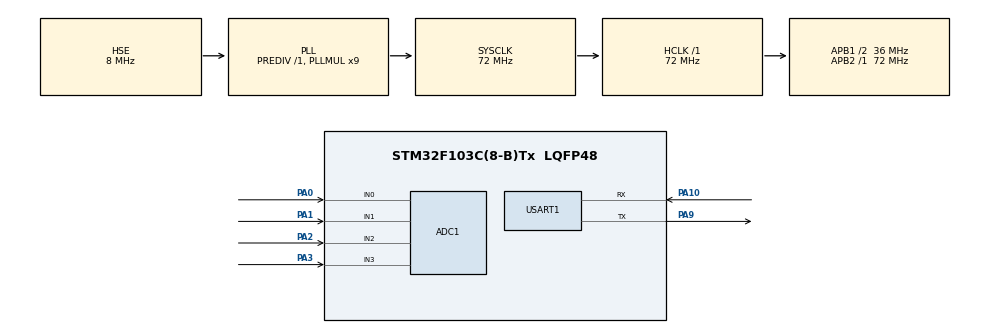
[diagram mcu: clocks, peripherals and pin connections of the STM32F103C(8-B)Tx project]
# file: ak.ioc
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ADC1.Channel-10\#ChannelRegularConversion=ADC_CHANNEL_0
ADC1.Channel-11\#ChannelRegularConversion=ADC_CHANNEL_0
ADC1.Channel-12\#ChannelRegularConversion=ADC_CHANNEL_0
ADC1.Channel-13\#ChannelRegularConversion=ADC_CHANNEL_0
ADC1.DiscontinuousConvMode=ENABLE
ADC1.NbrOfConversion=4
ADC1.NbrOfConversionFlag=1
ADC1.Rank-10\#ChannelRegularConversion=1
ADC1.Rank-11\#ChannelRegularConversion=2
ADC1.Rank-12\#ChannelRegularConversion=3
ADC1.Rank-13\#ChannelRegularConversion=4
ADC1.SamplingTime-10\#ChannelRegularConversion=ADC_SAMPLETIME_1CYCLE_5
ADC1.SamplingTime-11\#ChannelRegularConversion=ADC_SAMPLETIME_1CYCLE_5
ADC1.SamplingTime-12\#ChannelRegularConversion=ADC_SAMPLETIME_1CYCLE_5
ADC1.SamplingTime-13\#ChannelRegularConversion=ADC_SAMPLETIME_1CYCLE_5
ADC1.master=1
Dma.ADC1.0.Direction=DMA_PERIPH_TO_MEMORY
Dma.ADC1.0.Instance=DMA1_Channel1
Dma.ADC1.0.MemDataAlignment=DMA_MDATAALIGN_HALFWORD
Dma.ADC1.0.MemInc=DMA_MINC_ENABLE
Dma.ADC1.0.Mode=DMA_NORMAL
Dma.ADC1.0.PeriphDataAlignment=DMA_PDATAALIGN_HALFWORD
Dma.ADC1.0.PeriphInc=DMA_PINC_DISABLE
Dma.ADC1.0.Priority=DMA_PRIORITY_LOW
Dma.Request0=ADC1
Mcu.Family=STM32F1
Mcu.Name=STM32F103C(8-B)Tx
Mcu.Package=LQFP48
NVIC.DMA1_Channel1_IRQn=true\:0\:0\:false\:false\:true\:false\:true\:true
NVIC.PriorityGroup=NVIC_PRIORITYGROUP_4
NVIC.USART1_IRQn=true\:0\:0\:false\:false\:true\:true\:true\:true
PA0-WKUP.Signal=ADCx_IN0
PA1.Signal=ADCx_IN1
PA10.Mode=Asynchronous
PA10.Signal=USART1_RX
PA2.Signal=ADCx_IN2
PA3.Signal=ADCx_IN3
PA9.Mode=Asynchronous
PA9.Signal=USART1_TX
PD0-OSC_IN.Mode=HSE-External-Oscillator
PD0-OSC_IN.Signal=RCC_OSC_IN
PD1-OSC_OUT.Mode=HSE-External-Oscillator
PD1-OSC_OUT.Signal=RCC_OSC_OUT
ProjectManager.HeapSize=0x200
ProjectManager.StackSize=0x400
ProjectManager.TargetToolchain=MDK-ARM V5.32
RCC.ADCPresc=RCC_ADCPCLK2_DIV6
RCC.AHBFreq_Value=72000000
RCC.APB1CLKDivider=RCC_HCLK_DIV2
RCC.APB1Freq_Value=36000000
RCC.APB1TimFreq_Value=72000000
RCC.APB2Freq_Value=72000000
RCC.APB2TimFreq_Value=72000000
RCC.HCLKFreq_Value=72000000
RCC.PLLMUL=RCC_PLL_MUL9
RCC.PLLSourceVirtual=RCC_PLLSOURCE_HSE
RCC.SYSCLKFreq_VALUE=72000000
RCC.SYSCLKSource=RCC_SYSCLKSOURCE_PLLCLK
RCC.USBFreq_Value=72000000
SH.ADCx_IN0.0=ADC1_IN0,IN0
SH.ADCx_IN1.0=ADC1_IN1,IN1
SH.ADCx_IN2.0=ADC1_IN2,IN2
SH.ADCx_IN3.0=ADC1_IN3,IN3
USART1.VirtualMode=VM_ASYNC
VP_SYS_VS_ND.Mode=No_Debug
board=custom

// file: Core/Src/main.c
/* USER CODE BEGIN Header */
/**
  ******************************************************************************
  * @file           : main.c
  * @brief          : Main program body
  ******************************************************************************
  * @attention
  *
  * Copyright (c) 2022 STMicroelectronics.
  * All rights reserved.
  *
  * This software is licensed under terms that can be found in the LICENSE file
  * in the root directory of this software component.
  * If no LICENSE file comes with this software, it is provided AS-IS.
  *
  ******************************************************************************
  */
/* USER CODE END Header */
#include "main.h"
#include "string.h"
#include "stdio.h"

ADC_HandleTypeDef hadc1;
DMA_HandleTypeDef hdma_adc1;

UART_HandleTypeDef huart1;

void SystemClock_Config(void);
static void MX_GPIO_Init(void);
static void MX_DMA_Init(void);
static void MX_USART1_UART_Init(void);
static void MX_ADC1_Init(void);
/* USER CODE BEGIN PFP */
uint8_t ADC[10] = {0};
/* USER CODE END PFP */

/* USER CODE BEGIN 0 */
volatile uint16_t adcReadVal[4] = {0};
const int adcChannelCount = sizeof(adcReadVal)/sizeof(adcReadVal[0]);
volatile char adcConversionComplete = 0;
char txBuffer[36] = {0};
/* USER CODE END 0 */

int main(void)
{

  /* MCU Configuration--------------------------------------------------------*/

  /* Reset of all peripherals, Initializes the Flash interface and the Systick. */
  HAL_Init();

  /* Configure the system clock */
  SystemClock_Config();

  /* Initialize all configured peripherals */
  MX_GPIO_Init();
  MX_DMA_Init();
  MX_USART1_UART_Init();
  MX_ADC1_Init();
  /* Infinite loop */
  while (1)
  {
		HAL_ADC_Start_DMA(&hadc1,(uint32_t*)adcReadVal,adcChannelCount);
//		while(adcConversionComplete == 0)
//		{
//
//		}
		snprintf(txBuffer,sizeof(txBuffer),"CH0:%d,CH1:%d,CH2:%d,CH3:%d\n\r",adcReadVal[0],adcReadVal[1],adcReadVal[2],adcReadVal[3]);
		HAL_UART_Transmit(&huart1,(uint8_t*)txBuffer,strlen(txBuffer),HAL_MAX_DELAY);
		HAL_Delay(1000);
  }
}

void HAL_ADC_ConvCpltCallback(ADC_HandleTypeDef *hadc)
{
	adcConversionComplete = 1;
}
void SystemClock_Config(void)
{
  RCC_OscInitTypeDef RCC_OscInitStruct = {0};
  RCC_ClkInitTypeDef RCC_ClkInitStruct = {0};
  RCC_PeriphCLKInitTypeDef PeriphClkInit = {0};

  /** Initializes the RCC Oscillators according to the specified parameters
  * in the RCC_OscInitTypeDef structure.
  */
  RCC_OscInitStruct.OscillatorType = RCC_OSCILLATORTYPE_HSE;
  RCC_OscInitStruct.HSEState = RCC_HSE_ON;
  RCC_OscInitStruct.HSEPredivValue = RCC_HSE_PREDIV_DIV1;
  RCC_OscInitStruct.HSIState = RCC_HSI_ON;
  RCC_OscInitStruct.PLL.PLLState = RCC_PLL_ON;
  RCC_OscInitStruct.PLL.PLLSource = RCC_PLLSOURCE_HSE;
  RCC_OscInitStruct.PLL.PLLMUL = RCC_PLL_MUL9;
  if (HAL_RCC_OscConfig(&RCC_OscInitStruct) != HAL_OK)
  {
    Error_Handler();
  }

  /** Initializes the CPU, AHB and APB buses clocks
  */
  RCC_ClkInitStruct.ClockType = RCC_CLOCKTYPE_HCLK|RCC_CLOCKTYPE_SYSCLK
                              |RCC_CLOCKTYPE_PCLK1|RCC_CLOCKTYPE_PCLK2;
  RCC_ClkInitStruct.SYSCLKSource = RCC_SYSCLKSOURCE_PLLCLK;
  RCC_ClkInitStruct.AHBCLKDivider = RCC_SYSCLK_DIV1;
  RCC_ClkInitStruct.APB1CLKDivider = RCC_HCLK_DIV2;
  RCC_ClkInitStruct.APB2CLKDivider = RCC_HCLK_DIV1;

  if (HAL_RCC_ClockConfig(&RCC_ClkInitStruct, FLASH_LATENCY_2) != HAL_OK)
  {
    Error_Handler();
  }
  PeriphClkInit.PeriphClockSelection = RCC_PERIPHCLK_ADC;
  PeriphClkInit.AdcClockSelection = RCC_ADCPCLK2_DIV6;
  if (HAL_RCCEx_PeriphCLKConfig(&PeriphClkInit) != HAL_OK)
  {
    Error_Handler();
  }
}

static void MX_ADC1_Init(void)
{

  ADC_ChannelConfTypeDef sConfig = {0};

  /** Common config
  */
  hadc1.Instance = ADC1;
  hadc1.Init.ScanConvMode = ADC_SCAN_ENABLE;
  hadc1.Init.ContinuousConvMode = DISABLE;
  hadc1.Init.DiscontinuousConvMode = ENABLE;
  hadc1.Init.NbrOfDiscConversion = 1;
  hadc1.Init.ExternalTrigConv = ADC_SOFTWARE_START;
  hadc1.Init.DataAlign = ADC_DATAALIGN_RIGHT;
  hadc1.Init.NbrOfConversion = 4;
  if (HAL_ADC_Init(&hadc1) != HAL_OK)
  {
    Error_Handler();
  }

  /** Configure Regular Channel
  */
  sConfig.Channel = ADC_CHANNEL_0;
  sConfig.Rank = ADC_REGULAR_RANK_1;
  sConfig.SamplingTime = ADC_SAMPLETIME_1CYCLE_5;
  if (HAL_ADC_ConfigChannel(&hadc1, &sConfig) != HAL_OK)
  {
    Error_Handler();
  }

  /** Configure Regular Channel
  */
  sConfig.Rank = ADC_REGULAR_RANK_2;
  if (HAL_ADC_ConfigChannel(&hadc1, &sConfig) != HAL_OK)
  {
    Error_Handler();
  }

  /** Configure Regular Channel
  */
  sConfig.Rank = ADC_REGULAR_RANK_3;
  if (HAL_ADC_ConfigChannel(&hadc1, &sConfig) != HAL_OK)
  {
    Error_Handler();
  }

  /** Configure Regular Channel
  */
  sConfig.Rank = ADC_REGULAR_RANK_4;
  if (HAL_ADC_ConfigChannel(&hadc1, &sConfig) != HAL_OK)
  {
    Error_Handler();
  }

}

static void MX_USART1_UART_Init(void)
{

  huart1.Instance = USART1;
  huart1.Init.BaudRate = 115200;
  huart1.Init.WordLength = UART_WORDLENGTH_8B;
  huart1.Init.StopBits = UART_STOPBITS_1;
  huart1.Init.Parity = UART_PARITY_NONE;
  huart1.Init.Mode = UART_MODE_TX_RX;
  huart1.Init.HwFlowCtl = UART_HWCONTROL_NONE;
  huart1.Init.OverSampling = UART_OVERSAMPLING_16;
  if (HAL_UART_Init(&huart1) != HAL_OK)
  {
    Error_Handler();
  }

}

static void MX_DMA_Init(void)
{

  /* DMA controller clock enable */
  __HAL_RCC_DMA1_CLK_ENABLE();

  /* DMA interrupt init */
  /* DMA1_Channel1_IRQn interrupt configuration */
  HAL_NVIC_SetPriority(DMA1_Channel1_IRQn, 0, 0);
  HAL_NVIC_EnableIRQ(DMA1_Channel1_IRQn);

}

static void MX_GPIO_Init(void)
{

  /* GPIO Ports Clock Enable */
  __HAL_RCC_GPIOD_CLK_ENABLE();
  __HAL_RCC_GPIOA_CLK_ENABLE();

}

void Error_Handler(void)
{
  __disable_irq();
  while (1)
  {
  }
}
